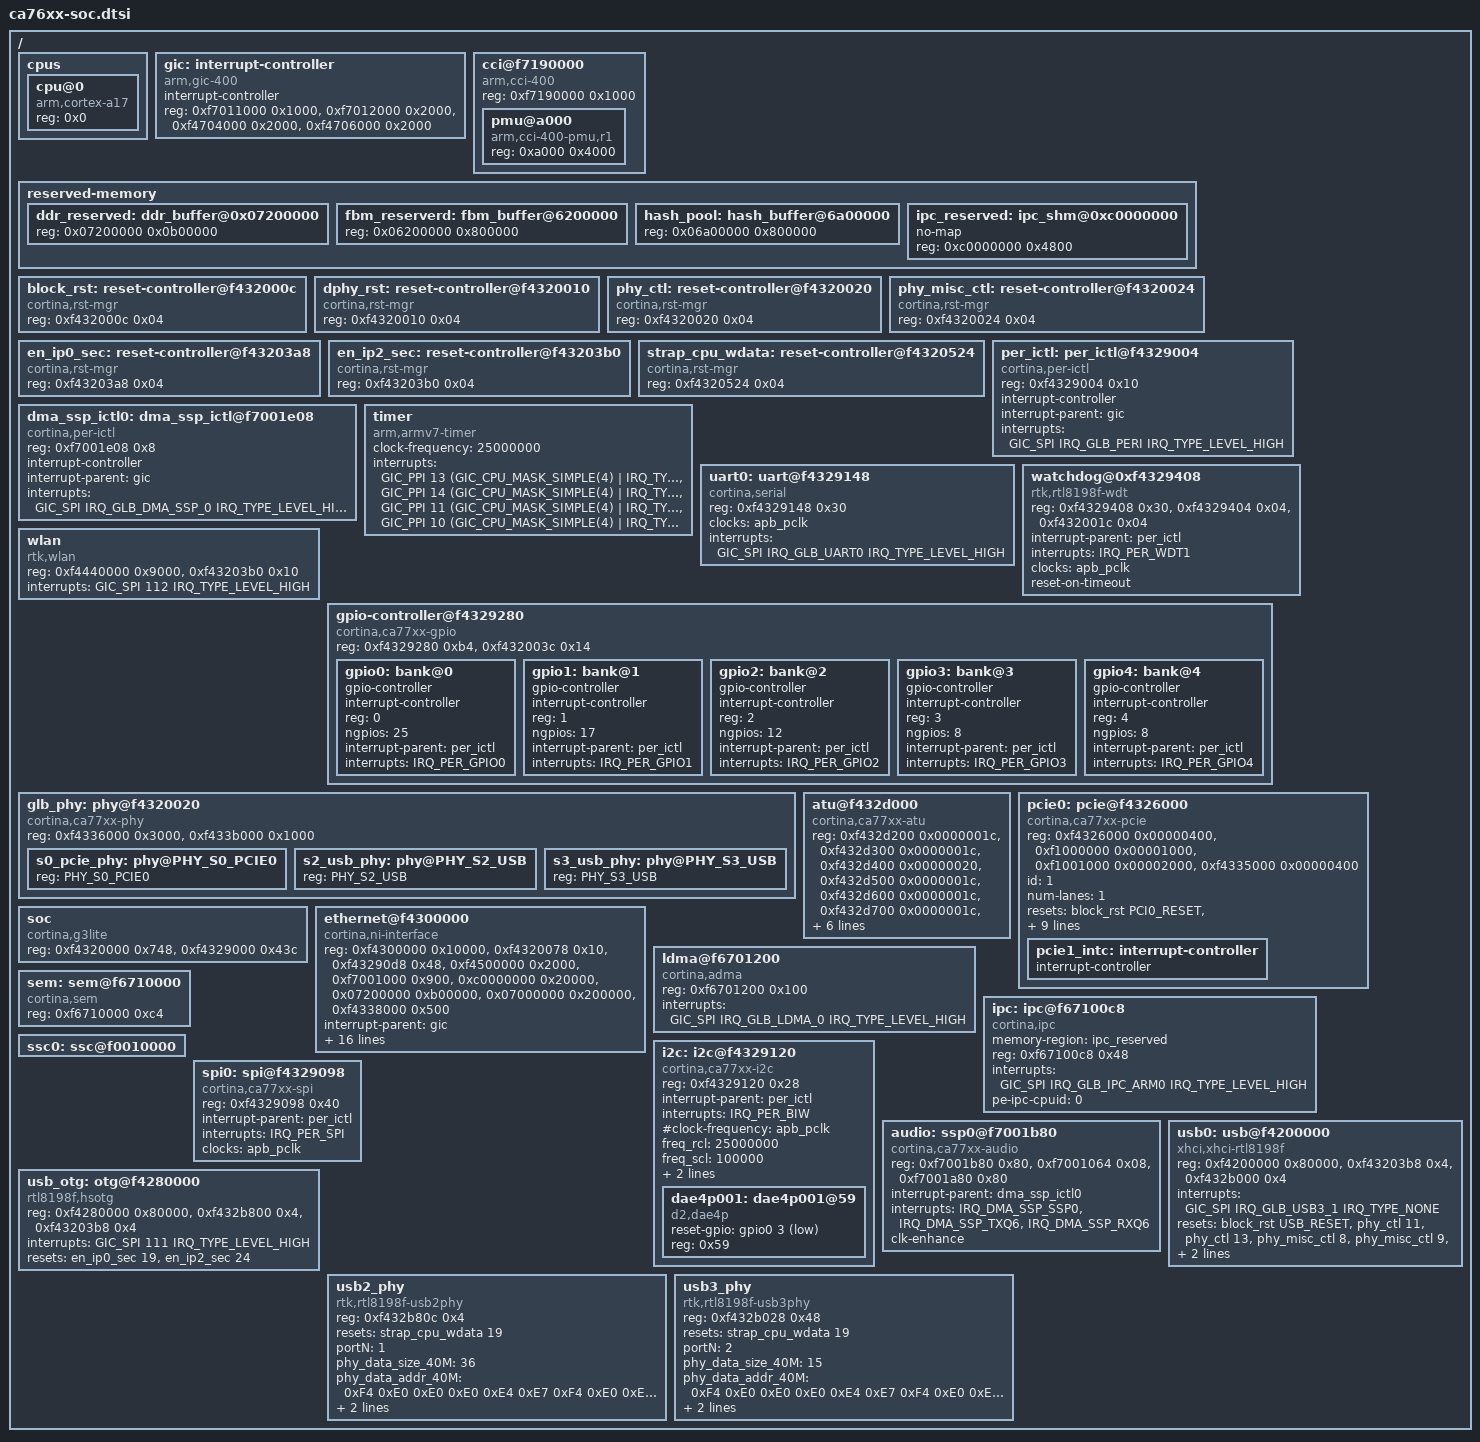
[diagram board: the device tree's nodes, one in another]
/*
 * dts file for Cortina Access CA76xx SoC
 *
 * Copyright (C) 2016, Cortina Access
 */

#include <dt-bindings/soc/cortina_irqs.h>
#include <dt-bindings/interrupt-controller/arm-gic.h>
#include <dt-bindings/interrupt-controller/irq.h>
#include <dt-bindings/reset/cortina,rst-mgr.h>
#include <dt-bindings/phy/phy-ca77xx.h>

/ {
	/* explained in Documentation/devicetree/bindings/arm/cpus.txt */
	/* topology explained in Documentation/devicetree/bindings/arm/topology.txt */
	/* TODO: cpufreq voltage and freq scaling, see Documentation/devicetree/bindings/cpufreq/cpufreq-dt.txt */
	cpus {
		#address-cells = <1>;
		#size-cells = <0>;

		cpu@0 {
			device_type = "cpu";
			compatible = "arm,cortex-a17";
			reg = <0x0>;
		};
	};

	gic: interrupt-controller {
		compatible = "arm,gic-400", "arm,cortex-a15-gic";
		interrupt-controller;
		#interrupt-cells = <3>;
		reg = <0xf7011000 0x1000>, /* GICD */
		      <0xf7012000 0x2000>, /* GICC */
		      <0xf4704000 0x2000>, /* GICH */
		      <0xf4706000 0x2000>; /* GICV */
	};

	cci@f7190000 {
		compatible = "arm,cci-400";
		#address-cells = <1>;
		#size-cells = <1>;
		reg = <0xf7190000 0x1000>;
		ranges = <0x0 0xf7190000 0x10000>;

		pmu@a000 {
			compatible = "arm,cci-400-pmu,r1", "arm,cci-400-pmu";
			reg = <0xa000 0x4000>;
		};
	};

	/* Reserver memory region for Hash/FBM/NE and etc.
	 * Fixme when NE team finalize size and offset
	 */
	reserved-memory {
		#address-cells = <1>;
		#size-cells = <1>;
		ranges;

		ddr_reserved: ddr_buffer@0x07200000 {
			reg = <0x07200000 0x0b00000>;    /* reserved memory area in DDR $-coherent */
		};

		fbm_reserverd: fbm_buffer@6200000 {
			reg = <0x06200000 0x800000>;
		};

		hash_pool: hash_buffer@6a00000 {
			reg = <0x06a00000 0x800000>;
		};

		ipc_reserved: ipc_shm@0xc0000000 {
			no-map;
			reg = <0xc0000000 0x4800>;
		};
	};

	/* Block Reset */
	block_rst: reset-controller@f432000c {
		compatible = "cortina,rst-mgr";
		reg = <0xf432000c 0x04>;
		#reset-cells = <1>;
	};

	/* DPHY Reset */
	dphy_rst: reset-controller@f4320010 {
		compatible = "cortina,rst-mgr";
		reg = <0xf4320010 0x04>;
		#reset-cells = <1>;
	};

	/* Global PHY Control */
	phy_ctl: reset-controller@f4320020 {
		compatible = "cortina,rst-mgr";
		reg = <0xf4320020 0x04>;
		#reset-cells = <1>;
	};

	/* Global Phy Misc Control */
	phy_misc_ctl: reset-controller@f4320024 {
		compatible = "cortina,rst-mgr";
		reg = <0xf4320024 0x04>;
		#reset-cells = <1>;
	};

	/* Global Enable Ip 0 Secure Register */
	en_ip0_sec: reset-controller@f43203a8 {
		compatible = "cortina,rst-mgr";
		reg = <0xf43203a8 0x04>;
		#reset-cells = <1>;
	};

	/* Global Enable Ip 2 Secure Register */
	en_ip2_sec: reset-controller@f43203b0 {
		compatible = "cortina,rst-mgr";
		reg = <0xf43203b0 0x04>;
		#reset-cells = <1>;
	};

#if 1
	/* STRAP_CPU_WDATA */
	strap_cpu_wdata: reset-controller@f4320524 {
		compatible = "cortina,rst-mgr";
		reg = <0xf4320524 0x04>;
		#reset-cells = <1>;
	};
#endif

	/* Peripheral interrupts */
	per_ictl: per_ictl@f4329004 {
		compatible = "cortina,per-ictl";
		reg = <0xf4329004 0x10>;
		interrupt-controller;
		#interrupt-cells = <1>;
		interrupt-parent = <&gic>;
		interrupts = <GIC_SPI IRQ_GLB_PERI IRQ_TYPE_LEVEL_HIGH>;
	};

	/* DMA SSP 0 interrupts */
	dma_ssp_ictl0: dma_ssp_ictl@f7001e08 {
		compatible = "cortina,per-ictl";
		reg = <0xf7001e08 0x8>;
		interrupt-controller;
		#interrupt-cells = <1>;
		interrupt-parent = <&gic>;
		interrupts = <GIC_SPI IRQ_GLB_DMA_SSP_0 IRQ_TYPE_LEVEL_HIGH>;
	};

#if 0
	/* NE interrupts, offset is GLOBAL_NETWORK_ENGINE_INTERRUPT_0 */
	ne_ictl: ne_ictl@f43200a0 {
		compatible = "cortina,per-ictl";
		reg = <0x0 0xf43200a0  0x0 0x10>;
		interrupt-controller;
		#interrupt-cells = <1>;
		interrupt-parent = <&gic>;
		interrupts = <GIC_SPI IRQ_GLB_NE IRQ_TYPE_LEVEL_HIGH>;
	};
#endif
	/* ARM V7 timer explained here /Documentation/devicetree/bindings/arm/arch_timer.txt */
	timer {
		compatible = "arm,armv7-timer";
		clock-frequency = <25000000>;
		interrupts = <GIC_PPI 13 (GIC_CPU_MASK_SIMPLE(4) | IRQ_TYPE_LEVEL_LOW)>,
			     <GIC_PPI 14 (GIC_CPU_MASK_SIMPLE(4) | IRQ_TYPE_LEVEL_LOW)>,
			     <GIC_PPI 11 (GIC_CPU_MASK_SIMPLE(4) | IRQ_TYPE_LEVEL_LOW)>,
			     <GIC_PPI 10 (GIC_CPU_MASK_SIMPLE(4) | IRQ_TYPE_LEVEL_LOW)>;
	};

	uart0: uart@f4329148 { /* console */
		device_type = "serial";
		compatible = "cortina,serial";
		reg = <0xf4329148 0x30>; /* TODO - update when memory map available */
		clocks = <&apb_pclk>;
		interrupts = <GIC_SPI IRQ_GLB_UART0 IRQ_TYPE_LEVEL_HIGH>; /* TODO - update when interrupt map available */
	};

	watchdog@0xf4329408 { /* Linux WDT */
		compatible = "rtk,rtl8198f-wdt";
		reg = <0xf4329408 0x30>,
		      <0xf4329404 0x04>,
		      <0xf432001c 0x04>;
		interrupt-parent = <&per_ictl>;
		interrupts = <IRQ_PER_WDT1>;
		clocks = <&apb_pclk>;
		reset-on-timeout;
	};

	wlan {
		device_type = "wlan";
		compatible = "rtk,wlan";
		reg = <0xf4440000 0x9000>,
		      <0xf43203b0 0x10>;
		interrupts = <GIC_SPI 112 IRQ_TYPE_LEVEL_HIGH>;
	};

	gpio-controller@f4329280 {
		#address-cells = <1>;
		#size-cells = <0>;
		compatible = "cortina,ca77xx-gpio";
		reg = <0xf4329280 0xb4>,
		      <0xf432003c 0x14>;

		/* bank 0 with an interrupt */
		gpio0: bank@0 {
			gpio-controller;
			interrupt-controller;
			reg = <0>;
			ngpios = <25>;
			#gpio-cells = <2>;
			#interrupt-cells = <2>;
			interrupt-parent = <&per_ictl>;
			interrupts = <IRQ_PER_GPIO0>;
		};

		/* bank 1 with an interrupt */
		gpio1: bank@1 {
			gpio-controller;
			interrupt-controller;
			reg = <1>;
			ngpios = <17>;
			#gpio-cells = <2>;
			#interrupt-cells = <2>;
			interrupt-parent = <&per_ictl>;
			interrupts = <IRQ_PER_GPIO1>;
		};

		/* bank 2 without interrupt */
		gpio2: bank@2 {
			gpio-controller;
			interrupt-controller;
			reg = <2>;
			ngpios = <12>;
			#gpio-cells = <2>;
			#interrupt-cells = <2>;
			interrupt-parent = <&per_ictl>;
			interrupts = <IRQ_PER_GPIO2>;
		};

		/* bank 3 without interrupt */
		gpio3: bank@3 {
			gpio-controller;
			interrupt-controller;
			reg = <3>;
			ngpios = <8>;
			#gpio-cells = <2>;
			#interrupt-cells = <2>;
			interrupt-parent = <&per_ictl>;
			interrupts = <IRQ_PER_GPIO3>;
		};

		/* bank 4 without interrupt */
		gpio4: bank@4 {
			gpio-controller;
			interrupt-controller;
			reg = <4>;
			ngpios = <8>;
			#gpio-cells = <2>;
			#interrupt-cells = <2>;
			interrupt-parent = <&per_ictl>;
			interrupts = <IRQ_PER_GPIO4>;
		};
	};

	/* explained in Documentation/devicetree/bindings/phy/ca77xx-phy.txt */
	glb_phy: phy@f4320020 {
		#address-cells = <1>;
		#size-cells = <0>;
		compatible = "cortina,ca77xx-phy";
		reg = 
#if 0
		      <0xf4320020 0x18>,	/* TODO: it's shared reg */
#endif
		      <0xf4336000 0x3000>,
		      <0xf433b000 0x1000>;

		s0_pcie_phy: phy@PHY_S0_PCIE0 {
			reg = <PHY_S0_PCIE0>;
			#phy-cells = <0>;
		};

#if 0
		s1_pcie_phy: phy@PHY_S1_PCIE0 {
			reg = <PHY_S1_PCIE0>;
			#phy-cells = <0>;
		};

		s2_pcie_phy: phy@PHY_S2_PCIE0 {
			reg = <PHY_S2_PCIE0>;
			#phy-cells = <0>;
		};
#endif

		s2_usb_phy: phy@PHY_S2_USB {
			reg = <PHY_S2_USB>;
			#phy-cells = <0>;
		};

		s3_usb_phy: phy@PHY_S3_USB {
			reg = <PHY_S3_USB>;
			#phy-cells = <0>;
		};
	};

	atu@f432d000 {
		compatible = "cortina,ca77xx-atu";
		reg = <0xf432d200 0x0000001c>,
		      <0xf432d300 0x0000001c>,
		      <0xf432d400 0x00000020>,
		      <0xf432d500 0x0000001c>,
		      <0xf432d600 0x0000001c>,
		      <0xf432d700 0x0000001c>,
		      <0xf432d800 0x0000001c>,
		      <0xf6700000 0x00000020>,
		      <0xf6700200 0x00000020>,
		      <0xf6700400 0x00000020>;
		reg-names = "pcie1_atu", "gdma_atu", "wlan_top_atu", "sd_atu",
			    "usb0_atu", "usb1_atu", "lxip_atu", "pe0_atu",
			    "crypto0_atu", "crypto1_atu";
		atu-type = "axi_std", "ahb_plus", "axi_plus", "ahb_plus",
			   "axi_std", "ahb_plus", "ahb_plus", "axi_plus",
			   "axi_plus", "axi_plus";
	};

	/* Synopsis Designware PCIe interface */
	/* explained in Documentation/devicetree/bindings/pci/ca77xx-pcie.txt */
	pcie0: pcie@f4326000 {
		compatible = "cortina,ca77xx-pcie";
		reg = <0xf4326000 0x00000400>,
		      <0xf1000000 0x00001000>,
		      <0xf1001000 0x00002000>,
		      <0xf4335000 0x00000400>;
		reg-names = "glbl_regs", "rc_dbi", "config", "serdes_phy";
		#address-cells = <3>;
		#size-cells = <2>;
		device_type = "pci";
		ranges = <0x81000000 0 0          0xf1010000 0 0x00010000   /* downstream I/O */
			  0x82000000 0 0xf1020000 0xf1020000 0 0x00fed000>; /* non-prefetchable memory */

		id = <1>;
		num-lanes = <1>;

		//clocks = <&clks 144>, <&clks 206>, <&clks 189>;
		//clock-names = "pcie", "pcie_bus", "pcie_phy";
		//cortina,pcie-port = 0

		resets = <&block_rst PCI0_RESET>, <&dphy_rst PHY_S0_PCIE_RESET>;
		reset-names = "core_reset", "phy_reset";

		phys = <&s0_pcie_phy>;
		phy-names = "pcie-phy";

		interrupt-parent = <&gic>;
		interrupts = <GIC_SPI IRQ_GLB_PCI_1 IRQ_TYPE_LEVEL_HIGH>; /* controller interrupt */

		#interrupt-cells = <1>;
		interrupt-map-mask = <0 0 0 7>;
		interrupt-map = <0 0 0 1 &pcie1_intc 0>,
				<0 0 0 2 &pcie1_intc 1>,
				<0 0 0 3 &pcie1_intc 2>,
				<0 0 0 4 &pcie1_intc 3>;
		pcie1_intc: interrupt-controller {
			interrupt-controller;
			#address-cells = <0>;
			#interrupt-cells = <1>;
		};
	};

	soc {
		compatible = "cortina,g3lite";
		reg = <0xf4320000 0x748>,
		      <0xf4329000 0x43c>;
#if 0
		reg = <0xf4320000 0x4>,		/* GLOBAL_JTAG_ID */
		      <0xf43200fc 0x8>,		/* GLOBAL_SECURITY_OVERRIDE */
		      <0xf4320018 0x4>,		/* GLBOAL_STRAP */
		      <0xf4320528 0x4>;		/* GLOBAL_FW_CTRL */
		reg-names = "JTAG_ID", "SECURITY_OVERRIDE", "STRAP", "CLOCK";
#endif
	};

	ethernet@f4300000 {
		compatible = "cortina,ni-interface";

		#address-cells = <1>;
		#size-cells = <1>;

		reg = <0xf4300000 0x10000>,		/* reserved memory area for HV NE(APB0) module registers */
		      <0xf4320078 0x10>,		/* reserved memory area for Global Network Engine Interrupt registers */
		      <0xf43290d8 0x48>,		/* reserved memory area for MDIO registers */
		      <0xf4500000 0x2000>,		/* reserved memory area for XRAM */
		      <0xf7001000 0x900>,		/* reserved memory area for DMA LSO */
		      <0xc0000000 0x20000>,		/* reserved memory area in SRAM */
		      <0x07200000 0xb00000>,		/* reserved memory area in DDR $-coherent */
		      <0x07000000 0x200000>,		/* reserved memory area in DDR noncache-coherent, 8198F does not used */
		      <0xf4338000 0x500>;		/* reserved memory area for PHY registers */

		//interrupt-parent=<&ne_ictl>;
		//interrupts=<0>,			/* interupt for NI */
		//         <4>;				/* interrupt for TQM */
		interrupt-parent=<&gic>;
		interrupts=<GIC_SPI IRQ_GLB_QM_CPU_FIFO0_REQ IRQ_TYPE_LEVEL_HIGH>,
			   <GIC_SPI IRQ_GLB_QM_CPU_FIFO1_REQ IRQ_TYPE_LEVEL_HIGH>,
			   <GIC_SPI IRQ_GLB_QM_CPU_FIFO2_REQ IRQ_TYPE_LEVEL_HIGH>,
			   <GIC_SPI IRQ_GLB_QM_CPU_FIFO3_REQ IRQ_TYPE_LEVEL_HIGH>,
			   <GIC_SPI IRQ_GLB_QM_CPU_FIFO4_REQ IRQ_TYPE_LEVEL_HIGH>,
			   <GIC_SPI IRQ_GLB_QM_CPU_FIFO5_REQ IRQ_TYPE_LEVEL_HIGH>,
			   <GIC_SPI IRQ_GLB_QM_CPU_FIFO6_REQ IRQ_TYPE_LEVEL_HIGH>,
			   <GIC_SPI IRQ_GLB_QM_CPU_FIFO7_REQ IRQ_TYPE_LEVEL_HIGH>,
			   <GIC_SPI IRQ_GLB_QM_CPU_REFILL_REQ_8 IRQ_TYPE_LEVEL_HIGH>,
			   <GIC_SPI IRQ_GLB_QM_CPU_REFILL_REQ_9 IRQ_TYPE_LEVEL_HIGH>;

		resets = <&block_rst NI_RESET>, <&block_rst L2FE_RESET>, <&block_rst L2TM_RESET>, <&block_rst L3FE_RESET>, <&block_rst SDRAM_RESET>, <&block_rst TQM_RESET>, <&block_rst FBM_RESET>;
		reset-names = "ni_reset", "l2fe_reset", "l2tm_reset", "l3fe_reset", "sdram_reset", "tqm_reset", "fbm_reset";

		memory-region = <&ddr_reserved>;
	};

#if 1
	ldma@f6701200{
		compatible = "cortina,adma";
		reg = <0xf6701200 0x100>;
		interrupts = <GIC_SPI IRQ_GLB_LDMA_0 IRQ_TYPE_LEVEL_HIGH>;	/* Fixme: update when interrupt map available */
	};
#endif


	ipc: ipc@f67100c8 { /* IPC */
		compatible = "cortina,ipc";
		memory-region = <&ipc_reserved>;
		reg = <0xf67100c8 0x48>;				/* TODO - reserved for mailbox register*/
		interrupts = <GIC_SPI IRQ_GLB_IPC_ARM0 IRQ_TYPE_LEVEL_HIGH>;
		pe-ipc-cpuid = <0>;
	};

	sem: sem@f6710000 { /* Hardware Semaphore */
		compatible = "cortina,sem";
		reg = <0xf6710000 0xc4>;				/* TODO - reserved for semaphore register*/
	};

	ssc0: ssc@f0010000 {
		status = "okay";
	};

	/* TODO I2C interface - board specific */
	i2c: i2c@f4329120 {

		#address-cells = <1>;
		#size-cells = <0>;
		compatible = "cortina,ca77xx-i2c";
		reg = <0xf4329120 0x28>;
		interrupt-parent = <&per_ictl>;
		interrupts = <IRQ_PER_BIW>;
		device_type = "i2c";
		#clock-frequency = <&apb_pclk>;

		freq_rcl = <25000000>;		/* Reference Clock */
		freq_scl = <100000>;		/* Serial Clock */
		timeout  = <100>;		/* In milliseconds */
		retries  = <3>;			/* retry count */
		/*status = "ok";*/

		dae4p001: dae4p001@59 {
			compatible = "d2,dae4p";
			reset-gpio = <&gpio0 3 GPIO_ACTIVE_LOW>;
			reg = <0x59>;
		};
	};

	/* explained in Documentation/devicetree/bindings/spi/spi-bus.txt */
	spi0: spi@f4329098 {
		compatible = "cortina,ca77xx-spi";
		reg = <0xf4329098 0x40>;
		interrupt-parent = <&per_ictl>;
		interrupts = <IRQ_PER_SPI>;
		clocks = <&apb_pclk>;
		#address-cells = <1>;
		#size-cells = <0>;
	};

	audio: ssp0@f7001b80 {
		compatible = "cortina,ca77xx-audio";
		reg = <0xf7001b80 0x80>,
		      <0xf7001064 0x08>,
		      <0xf7001a80 0x80>;
		reg-names = "ssp", "dma-glb", "dma-ssp";

		interrupt-parent = <&dma_ssp_ictl0>;
		interrupts = <IRQ_DMA_SSP_SSP0>,
			     <IRQ_DMA_SSP_TXQ6>,
			     <IRQ_DMA_SSP_RXQ6>;
		interrupt-names = "ssp", "dma-tx", "dma-rx";
		clk-enhance;
	};

#if 0
	mmc0: mmc@f4400000 {
			compatible = "snps,dw-mshc";
			#address-cells = <1>;
			#size-cells = <0>;
			reg = <0xf4400000 0x1000>;
			interrupts = <GIC_SPI IRQ_GLB_SD IRQ_TYPE_LEVEL_HIGH>;
			clocks = <&sd_clk>, <&sd_clk>;
			clock-names = "ciu","biu";
			cd-gpios;
			num-slots = <1>;
			card-detect-delay = <200>;
			bus-width = <4>;
			cap-mmc-highspeed;
			cap-sd-highspeed;
		};

	sound {
		compatible = "cortina,ca77xx-evm-audio";
		cortina,model = "DAE4P-EVMSK";
		cortina,audio-codec = <&dae4p001>;
		cortina,ssc-controller = <&ssc0>;
		cortina,codec-clock-rate = <24000000>;
		cortina,audio-routing =
			"Headphone Jack",       "HPLOUT",
			"Headphone Jack",       "HPROUT";
	};

	ca77xx_evm0: ca77xx-i2s {
		compatible = "cortina,ca77xx-i2s";
	};

	ca77xx_pcm_audio: ca77xx_pcm_audio@0xf7001000 {
		.compatible = "cortina,ca77xx-pcm-audio";
	};
#endif

	usb0: usb@f4200000 {
		compatible = "xhci,xhci-rtl8198f";
		reg = <0xf4200000 0x80000>,
		      <0xf43203b8 0x4>,
		      <0xf432b000 0x4>;
		interrupts = <GIC_SPI IRQ_GLB_USB3_1 IRQ_TYPE_NONE>;
		resets = <&block_rst USB_RESET>,
			 <&phy_ctl 11>,
			 <&phy_ctl 13>,
			 <&phy_misc_ctl 8>,
			 <&phy_misc_ctl 9>,
			 <&en_ip2_sec 26>;
		reset-names = "core_reset",
			      "usb3_isolate",
			      "pow_usb3",
			      "u3_bg_en",
			      "u3_mbias_en",
			      "u3_suspend_clk";
		usb-phy = <&usb3_phy>;
	};

	usb_otg: otg@f4280000 {
		compatible = "rtl8198f,hsotg";
		reg = <0xf4280000 0x80000>,
		      <0xf432b800 0x4>,
		      <0xf43203b8 0x4>;
		interrupts = <GIC_SPI 111 IRQ_TYPE_LEVEL_HIGH>;
		resets = <&en_ip0_sec 19>,
			 <&en_ip2_sec 24>;
		reset-names = "usbotg_en",
			      "active_usbotg";
	};

	usb2_phy: usb2_phy {
		compatible = "rtk,rtl8198f-usb2phy";
		reg = <0xf432b80c 0x4>;
		reg-names = "phy0_reg";
		#address-cells = <1>;
		#size-cells = <1>;
		resets = <&strap_cpu_wdata 19>;
		reset-names = "strap_cpu_wdata";
		ranges;
		portN = <1>;
		phy_data_size_40M = <36>;
		phy_data_addr_40M = /bits/ 8
		<
		/* init */
		0xF4 0xE0 0xE0 0xE0 0xE4 0xE7 0xF4 0xE0 0xE0 0xE0
		/* page 0 */
		0xF4 0xE0 0xE1 0xE2 0xE3 0xE4 0xE5 0xE6 0xE7 0xF0 0xF1 0xF2 0xF3 0xF4 0xF5 0xF6 0xF7
		/* page 1 */
		0xF4 0xE0 0xE1 0xE2 0xE3 0xE4 0xE5 0xE6 0xE7
		>;
		phy_data_Array_40M = /bits/ 8
		<
		/* init */
		0x9B 0xE2 0x62 0xE2 0x8A 0x81 0xBB 0x25 0x21 0x25
		/* page 0 */
		0x9B 0xE2 0x31 0x5D 0x8D 0xCA 0x19 0xC9 0xA1 0xFC 0x8C 0x00 0x11 0x9B 0x15 0x00 0x0E
		/* page 1 */
		0xBB 0x25 0x4F 0x00 0x00 0x00 0x0A 0x18 0xE3
		>;
		status = "okay";
	};

	usb3_phy: usb3_phy {
		compatible = "rtk,rtl8198f-usb3phy";
		reg = <0xf432b028 0x48>;
		reg-names = "usbcfg_u2_base";
		#address-cells = <1>;
		#size-cells = <1>;
		resets = <&strap_cpu_wdata 19>;
		reset-names = "strap_cpu_wdata";
		ranges;
		portN = <2>;
		phy_data_size_40M = <15>;
		phy_data_addr_40M = /bits/ 8
		<
		/* init */
		0xF4 0xE0 0xE0 0xE0 0xE4 0xE7 0xF4 0xE0 0xE0 0xE0 0xF4
		/* asic A  */
		0xE2 0xE6 0xE4 0xE7
		>;
		phy_data_Array_40M = /bits/ 8
		<
		/* init */
		0x9B 0xE2 0x62 0xE2 0x8A 0x81 0xBB 0x25 0x21 0x25 0x9B
		/* asic A  */
		0x5D 0xC9 0xCA 0xA1
		>;
		status = "okay";
	};

#if 0	/* Cannot try until we got bitfile which support USB */
	usb@f4200000 {
		compatible = "cortina,dwusb3";
		ranges;
		usbdrd_dwc3: dwc3 {
			compatible = "synopsys,dwc3";
			reg = <0xf4200000 0x10000>;
			interrupts = <GIC_SPI IRQ_GLB_USB3_1 IRQ_TYPE_LEVEL_HIGH>;
			phys = <&usb2_phy>, <&usb3_phy>;
			phy-names = "usb2-phy", "usb3-phy";
			maximum-speed = "super-speed";
			dr_mode = "host";
		};
	};
#endif

#if 0
	smb {
		compatible = "simple-bus";
		#address-cells = <2>;
		#size-cells = <2>;
		interrupt-parent = <&gic>;
		ranges;

		uart2: uart@0xf4570174 {
			device_type = "serial";
			compatible = "cortina,serial";
			reg = <0xf4570174 0x30>; /* TODO - update when memory map available */
			clocks = <&apb_pclk>;
			interrupts = <0 32 0x1>; /* TODO - update when interrupt map available */
		};

		uart3: uart@0xf45701a4 {
			device_type = "serial";
			compatible = "cortina,serial";
			reg = <0xf45701a4 0x30>; /* TODO - update when memory map available */
			clocks = <&apb_pclk>;
			interrupts = <0 32 0x1>; /* TODO - update when interrupt map available */
		};

		/* Synopsis Designware SATA interface - ahci_platform.c  */
		/* explained in Documentation/devicetree/bindings/ata/ahci-platform.txt */
		/* TODO - revisit PHY configuration and clocks, when info available */
		sata0: sata@f4100000 {
			compatible = "snps,dwc-ahci";
			reg = <0xf4100000 0x800>;
			interrupts = <0 355 4>; /* TODO - update when interrupt map available */
			clocks = <&apb_pclk>;
			dma-coherent;
		};

		/* Synopsis Designware USB 2.0 interface */
		/* explained in Documentation/devicetree/bindings/usb/dwc2.txt */
		usb0: usb@f4200000 {
			compatible = "snps,dwc2";
			reg = <0xf4200000 0x10000>; /* TODO: revisit when memory map finalized */
			interrupts = <0 70 0x4>; /* TODO: revisit when irq map available */
			clocks = <&usb2_clk>;
			clock-names = "otg";
			/* TODO: revisit when PHY decided */
			/*
			phys = <&usbphy>;
			phy-names = "usb2-phy";
			*/
		};

		/* Synopsis Designware USB 3.0 interface */
		/* explained in Documentation/devicetree/bindings/usb/dwc3.txt */
		/* TODO: requires cortina specific glue logic driver to be developed */
		/* INCOMPLETE below, PHY driver and Glue logic. All comments out for now */
		usb1: usb@f4280000 {
			compatible = "cortina,g3-dwc3";
			#address-cells = <1>;
			#size-cells = <1>;
			reg = <0xf4280000 0x10000>;
			clocks = <&clkusb>;
			clock-names = "usb";
			interrupts = <0 393 1>;
			ranges;
			dma-coherent;
			dma-ranges;
			status = "disabled";

			dwc3@f4280000 {
				compatible = "synopsys,dwc3";
				reg = <0xf4280000 0x70000>;
				interrupts = <0 393 1>;
				usb-phy = <&usb3_phy>, <&usb3_phy>;
			};
		};

		usb3_phy: usb_phy@2620738 {
			compatible = "realtek,usb3phy";
			#address-cells = <1>;
			#size-cells = <1>;
			reg = <0x2620738 24>;
			status = "disabled";
		};
		*/
	};
	/* TODO list, some of these are going to be board specific and thus
	 * should be moved to the board specific device tree file like fpga
	 * board.
	 */
	/* TODO NI interface  - board specific phy config */
	/* TODO Temperture Monitor - board specific */
	/* TODO I2S/PCM interface  - board specific */
	/* TODO SPI interface - board specific */
	/* TODO I2C interface - board specific */
	/* TODO GPIO interface - board specific */
	/* TODO Clock tree - board specific */
#endif

};
